# STM32WBA62xx register map
File version: 1.0
Registers are 32-bit, read-write, reset 0x0 unless marked. A register's access mark holds for its fields unless they carry their own. Offsets are from the block's base; [hi:lo] are bit positions; {n}, {i} and the like mark numbered series.

## FLASH — FLASH Registers
Base 0x40022000
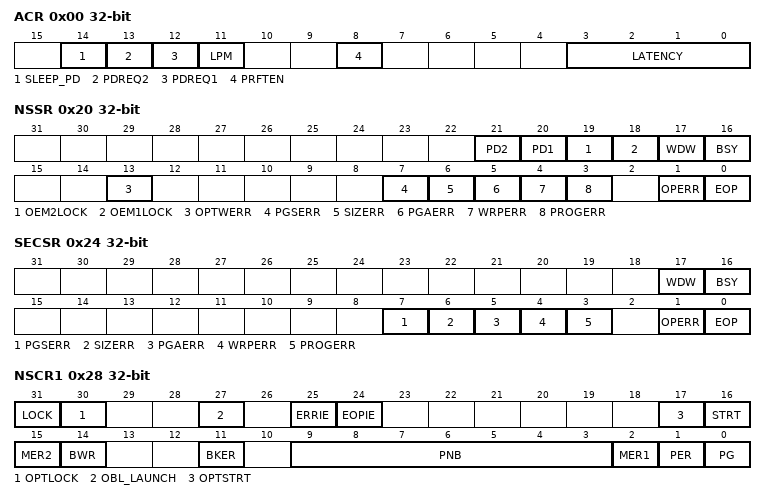
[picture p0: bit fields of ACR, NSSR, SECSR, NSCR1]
0x00 ACR — FLASH access control register
  [14] SLEEP_PD — Flash power-down mode during sleep
  [13] PDREQ2 — Flash bank 2 power-down mode request
  [12] PDREQ1 — Flash bank 1 power-down mode request
  [11] LPM — Low-Power read mode
  [8] PRFTEN — Prefetch enable
  [3:0] LATENCY
    0=FLASH Zero wait state; 1=FLASH One wait state; 2=FLASH Two wait states; 3=FLASH Three wait states; 4=FLASH Four wait states; 5=FLASH Five wait state; 6=FLASH Six wait state; 7=FLASH Seven wait states; 8=FLASH Eight wait states; 9=FLASH Nine wait states; 10=FLASH Ten wait state; 11=FLASH Eleven wait state; 12=FLASH Twelve wait states; 13=FLASH Thirteen wait states; 14=FLASH Fourteen wait states; 15=FLASH Fifteen wait states
0x08 NSKEYR — FLASH non-secure key register
  [31:0] NSKEY — Flash memory non-secure key
0x0C SECKEYR — FLASH secure key register
  [31:0] SECKEY — Flash memory secure key
0x10 OPTKEYR — FLASH option key register
  [31:0] OPTKEY — Option byte key
0x18 PDKEY1R — FLASH Bank 1 power-down key register
  [31:0] PDKEY — Flash bank 1 power-down key
0x1C PDKEY2R — FLASH Bank 2 power-down key register
  [31:0] PDKEY — Flash bank 2 power-down key
0x20 NSSR — FLASH non-secure status register
  [21] PD2 — Flash bank 2 in power-down mode
  [20] PD1 — Flash bank 1 in power-down mode
  [19] OEM2LOCK
  [18] OEM1LOCK
  [17] WDW — Non-secure wait data to write
  [16] BSY — Non-secure busy
  [13] OPTWERR — Option write error
  [7] PGSERR — Non-secure programming sequence error
  [6] SIZERR — Non-secure size error
  [5] PGAERR — Non-secure programming alignment error
  [4] WRPERR — Non-secure write protection error
  [3] PROGERR — Non-secure programming error
  [1] OPERR — Non-secure operation error
  [0] EOP — Non-secure end of operation
0x24 SECSR — FLASH secure status register
  [17] WDW — Secure wait data to write
  [16] BSY — Secure busy
  [7] PGSERR — Secure programming sequence error
  [6] SIZERR — Secure size error
  [5] PGAERR — Secure programming alignment error
  [4] WRPERR — Secure write protection error
  [3] PROGERR — Secure programming error
  [1] OPERR — Secure operation error
  [0] EOP — Secure end of operation
0x28 NSCR1 — FLASH non-secure control register
  [31] LOCK — Non-secure Lock
  [30] OPTLOCK — Option Lock
  [27] OBL_LAUNCH — Force the option byte loading
  [25] ERRIE — Non-secure error interrupt enable
  [24] EOPIE — Non-secure End of operation interrupt enable
  [17] OPTSTRT — Option Modification Start
  [16] STRT — Non-secure Start
  [15] MER2 — Non-secure Flash Bank 2 Erase
  [14] BWR — Non-secure Burst Write Programming mode
  [11] BKER — Non-secure Bank Selection for Page Erase
  [9:3] PNB — Non-secure Page Number selection
  [2] MER1 — Non-secure Flash Bank 1 Erase
  [1] PER — Non-secure Page Erase
  [0] PG — Non-secure Programming
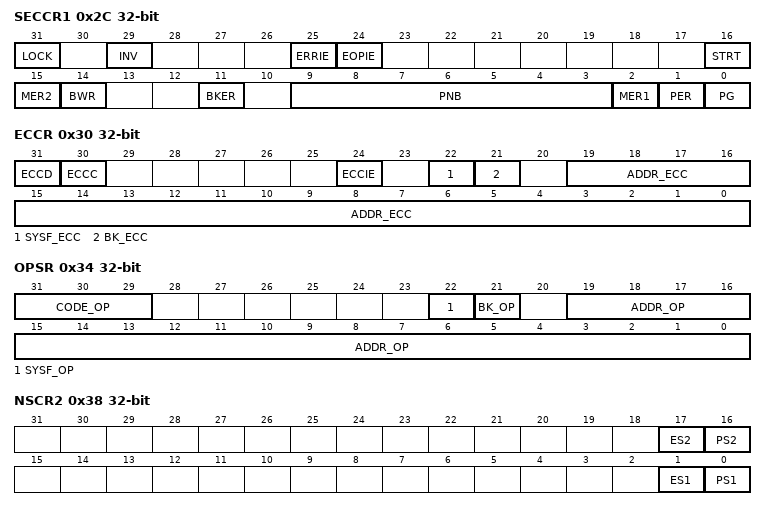
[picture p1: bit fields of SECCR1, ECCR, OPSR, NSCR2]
0x2C SECCR1 — FLASH secure control register
  [31] LOCK — Secure Lock
  [29] INV — Flash Security State Invert
  [25] ERRIE — Secure error interrupt enable
  [24] EOPIE — Secure end of operation interrupt enable
  [16] STRT — Secure Start
  [15] MER2 — Secure Flash Bank 2 Erase
  [14] BWR — Secure Burst Write programming mode
  [11] BKER — Secure Bank Selection for Page Erase
  [9:3] PNB — Secure Page Number selection
  [2] MER1 — Secure Flash Bank 1 Erase
  [1] PER — Secure Page Erase
  [0] PG — Secure Programming
0x30 ECCR — FLASH ECC register
  [31] ECCD — ECC detection
  [30] ECCC — ECC correction
  [24] ECCIE — ECC correction interrupt enable
  [22] SYSF_ECC — System Flash ECC fail
  [21] BK_ECC — Bank ECC fail
  [19:0] ADDR_ECC — ECC fail address
0x34 OPSR — FLASH OPSR register
  [31:29] CODE_OP — Flash memory operation code
  [22] SYSF_OP — Operation in system Flash memory interrupted
  [21] BK_OP — Operation in bank interrupted
  [19:0] ADDR_OP — Interrupted operation address
0x38 NSCR2 — FLASH non-secure control register
  [17] ES2 — Bank 2 non-secure erase suspend request
  [16] PS2 — Bank 2 non-secure program suspend request
  [1] ES1 — Bank 1 non-secure erase suspend request
  [0] PS1 — Bank 1 non-secure program suspend request
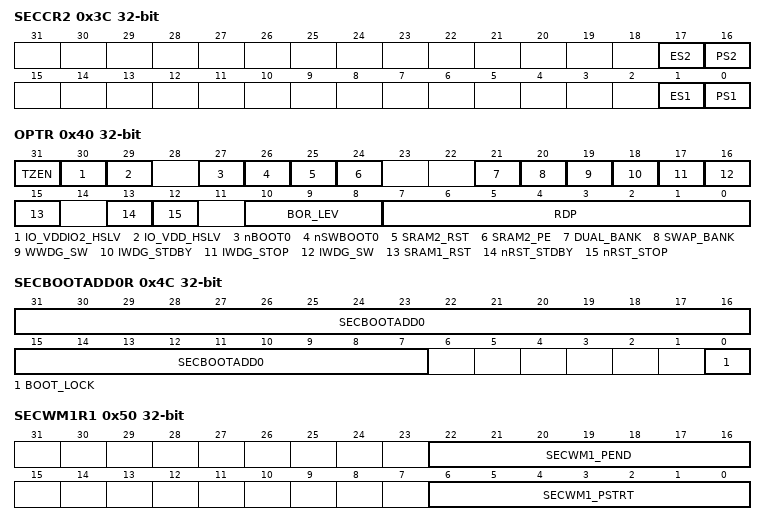
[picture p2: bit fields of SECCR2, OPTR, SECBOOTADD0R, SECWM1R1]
0x3C SECCR2 — FLASH secure control register
  [17] ES2 — Bank 2 secure erase suspend request
  [16] PS2 — Bank 2 secure program suspend request
  [1] ES1 — Bank 1 secure erase suspend request
  [0] PS1 — Bank 1 secure program suspend request
0x40 OPTR — FLASH option control register
  [31] TZEN — Global TrustZone security enable
  [30] IO_VDDIO2_HSLV — High-speed IO at low Vddio2 voltage configuration
  [29] IO_VDD_HSLV — High-speed IO at low Vdd voltage configuration
  [27] nBOOT0 — nBOOT0 option bit
  [26] nSWBOOT0 — Software BOOT0
  [25] SRAM2_RST — SRAM2 erase when system reset
  [24] SRAM2_PE — SRAM2 ECC detection and correction enable
  [21] DUAL_BANK
  [20] SWAP_BANK
  [19] WWDG_SW — Window watchdog selection
  [18] IWDG_STDBY — Independent watchdog counter freeze in Standby mode
  [17] IWDG_STOP — Independent watchdog counter freeze in Stop mode
  [16] IWDG_SW — Independent watchdog selection
  [15] SRAM1_RST — SRAM1 erase upon system reset
  [13] nRST_STDBY
  [12] nRST_STOP
  [10:8] BOR_LEV — BOR reset Level
  [7:0] RDP — Readout protection level
0x44 NSBOOTADD0R — FLASH non-secure boot address 0 register
  [31:7] NSBOOTADD0 — Non-secure boot address 0
0x48 NSBOOTADD1R — FLASH non-secure boot address 1 register
  [31:7] NSBOOTADD1 — Non-secure boot address 1
0x4C SECBOOTADD0R — FLASH secure boot address 0 register
  [31:7] SECBOOTADD0 — Secure boot address 0
  [0] BOOT_LOCK
0x50 SECWM1R1 — FLASH bank 1 secure watermark1 register 1
  [22:16] SECWM1_PEND — Bank 1 end page of secure area
  [6:0] SECWM1_PSTRT — Bank 1 start page of secure area
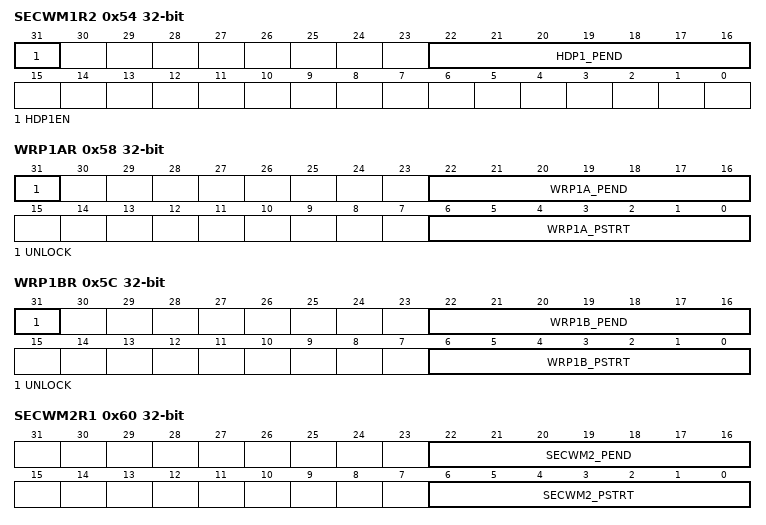
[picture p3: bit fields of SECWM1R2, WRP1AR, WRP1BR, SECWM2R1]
0x54 SECWM1R2 — FLASH bank 1 secure watermark1 register 2
  [31] HDP1EN — Bank 1 secure hide protection area enable
  [22:16] HDP1_PEND — Bank 1 end page of secure hide protection area
0x58 WRP1AR — FLASH WRP bank 1 area A address register
  [31] UNLOCK — WPR bank 1 area A unlock
  [22:16] WRP1A_PEND — WPR bank 1 area A end page
  [6:0] WRP1A_PSTRT — WPR bank 1 area A start page
0x5C WRP1BR — FLASH WRP bank 1 area B address register
  [31] UNLOCK — WPR bank 1 area B unlock
  [22:16] WRP1B_PEND — WPR bank 1 area B end page
  [6:0] WRP1B_PSTRT — WPR bank 1 area B start page
0x60 SECWM2R1 — FLASH bank 2 secure watermark2 register 1
  [22:16] SECWM2_PEND — Bank 2 end page of secure area
  [6:0] SECWM2_PSTRT — Bank 2 start page of secure area
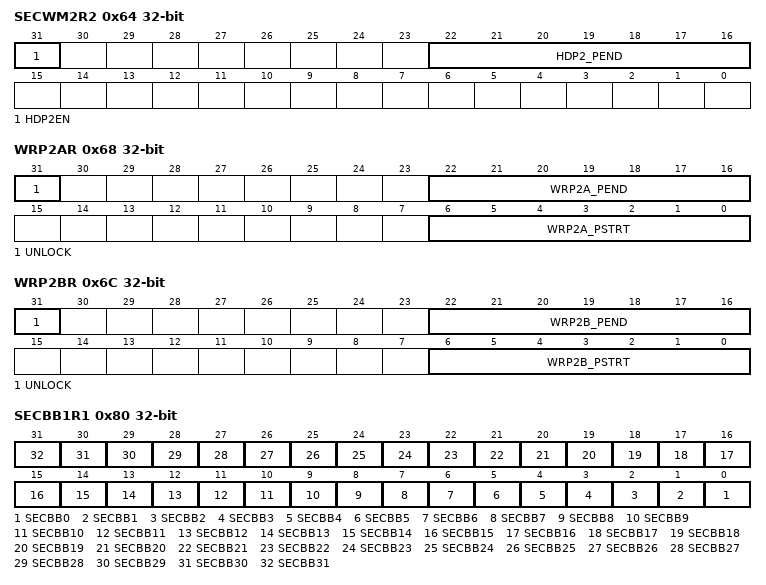
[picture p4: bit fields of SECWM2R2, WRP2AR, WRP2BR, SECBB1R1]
0x64 SECWM2R2 — FLASH bank 2 secure watermark2 register 2
  [31] HDP2EN — Bank 2 secure hide protection area enable
  [22:16] HDP2_PEND — Bank 2 end page of secure hide protection area
0x68 WRP2AR — FLASH WRP bank 2 area A address register
  [31] UNLOCK — WPR bank 2 area A unlock
  [22:16] WRP2A_PEND — WPR bank 2 area A end page
  [6:0] WRP2A_PSTRT — WPR bank 2 area A start page
0x6C WRP2BR — FLASH WRP bank 2 area B address register
  [31] UNLOCK — WPR bank 2 area B unlock
  [22:16] WRP2B_PEND — WPR bank 2 area B end page
  [6:0] WRP2B_PSTRT — WPR bank 2 area B start page
0x70 OEM1KEYR1 — FLASH OEM1 key register 1
  [31:0] OEM1KEY — OEM1 least significant bytes key
0x74 OEM1KEYR2 — FLASH OEM1 key register 2
  [31:0] OEM1KEY — OEM1 most significant bytes key
0x78 OEM2KEYR1 — FLASH OEM2 key register 1
  [31:0] OEM2KEY — OEM2 least significant bytes key
0x7C OEM2KEYR2 — FLASH OEM2 key register 2
  [31:0] OEM2KEY — OEM2 most significant bytes key
0x80 SECBB1R1 — FLASH bank 1 secure block-based bank register 1
  [n] SECBB{n} (n=0..31) — Page {n} in Flash bank 1 block-based secure
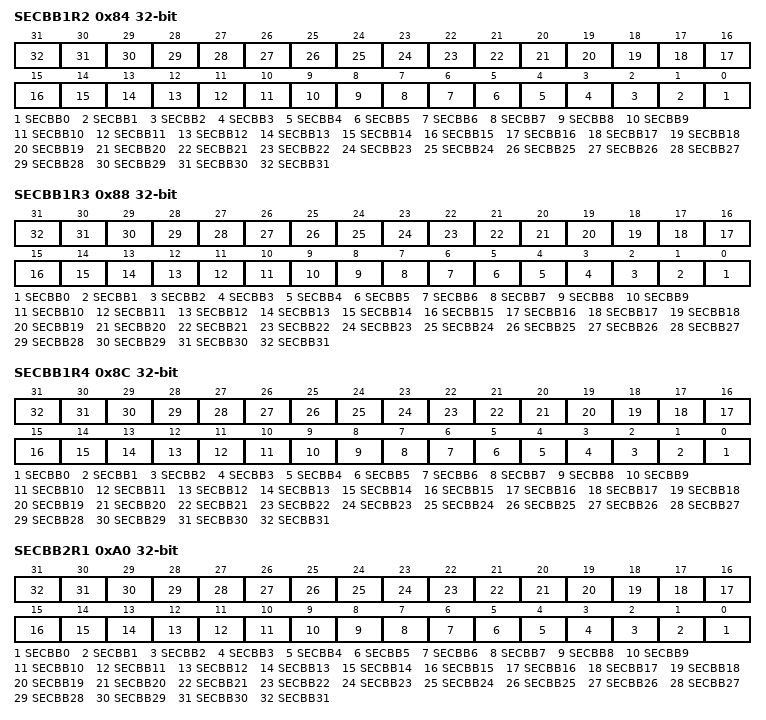
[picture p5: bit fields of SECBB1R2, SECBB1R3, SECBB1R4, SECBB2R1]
0x84 SECBB1R2 — FLASH bank 1 secure block-based bank register 2
  [n] SECBB{n} (n=0..31) — Page {n+32} in Flash bank 1 block-based secure
0x88 SECBB1R3 — FLASH bank 1 secure block-based bank register 3
  [n] SECBB{n} (n=0..31) — Page {n+64} in Flash bank 1 block-based secure
0x8C SECBB1R4 — FLASH bank 1 secure block-based bank register 4
  [n] SECBB{n} (n=0..31) — Page {n+96} in Flash bank 1 block-based secure
0xA0 SECBB2R1 — FLASH bank 2 secure block-based bank register 1
  [n] SECBB{n} (n=0..31) — Page {n} in Flash bank 2 block-based secure
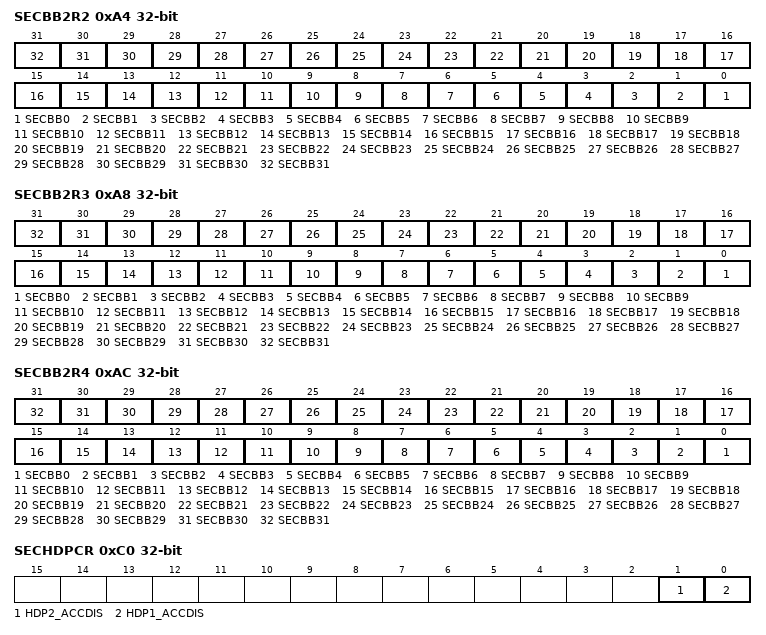
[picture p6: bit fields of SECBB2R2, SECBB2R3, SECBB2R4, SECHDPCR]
0xA4 SECBB2R2 — FLASH bank 2 secure block-based bank register 2
  [n] SECBB{n} (n=0..31) — Page {n+32} in Flash bank 2 block-based secure
0xA8 SECBB2R3 — FLASH bank 2 secure block-based bank register 3
  [n] SECBB{n} (n=0..31) — Page {n+64} in Flash bank 2 block-based secure
0xAC SECBB2R4 — FLASH bank 2 secure block-based bank register 4
  [n] SECBB{n} (n=0..31) — Page {n+96} in Flash bank 2 block-based secure
0xC0 SECHDPCR — FLASH secure HDP control register
  [1] HDP2_ACCDIS — Bank 2 secure HDP area access disable
  [0] HDP1_ACCDIS — Bank 1 secure HDP area access disable
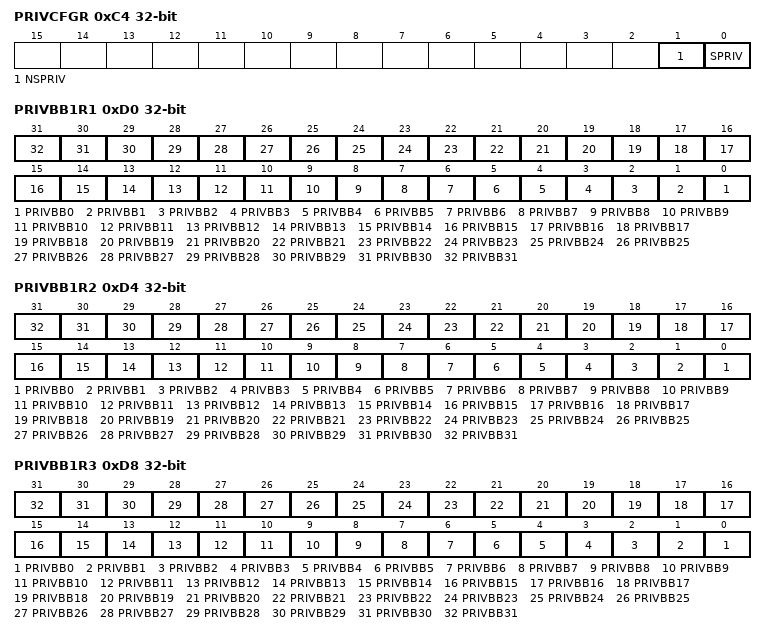
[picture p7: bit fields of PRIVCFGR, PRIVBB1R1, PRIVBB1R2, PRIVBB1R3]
0xC4 PRIVCFGR — FLASH privilege configuration register
  [1] NSPRIV — Privilege protection for non-secure registers
  [0] SPRIV — Privilege protection for secure registers
0xD0 PRIVBB1R1 — FLASH bank 1 privilege block-based bank register 1
  [n] PRIVBB{n} (n=0..31) — Page {n} in Flash bank 1 only accessible by privileged access
0xD4 PRIVBB1R2 — FLASH bank 1 privilege block-based bank register 2
  [n] PRIVBB{n} (n=0..31) — Page {n+32} in Flash bank 1 only accessible by privileged access
0xD8 PRIVBB1R3 — FLASH bank 1 privilege block-based bank register 3
  [n] PRIVBB{n} (n=0..31) — Page {n+64} in Flash bank 1 only accessible by privileged access
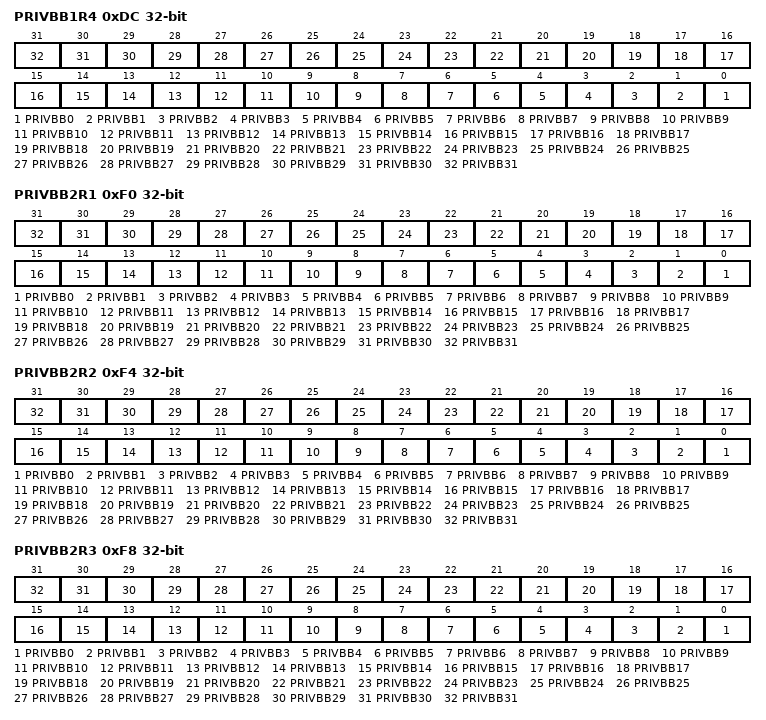
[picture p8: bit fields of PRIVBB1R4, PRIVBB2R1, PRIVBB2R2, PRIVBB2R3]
0xDC PRIVBB1R4 — FLASH bank 1 privilege block-based bank register 4
  [n] PRIVBB{n} (n=0..31) — Page {n+96} in Flash bank 1 only accessible by privileged access
0xF0 PRIVBB2R1 — FLASH bank 2 privilege block-based bank register 1
  [n] PRIVBB{n} (n=0..31) — Page {n} in Flash bank 2 only accessible by privileged access
0xF4 PRIVBB2R2 — FLASH bank 2 privilege block-based bank register 2
  [n] PRIVBB{n} (n=0..31) — Page {n+32} in Flash bank 2 only accessible by privileged access
0xF8 PRIVBB2R3 — FLASH bank 2 privilege block-based bank register 3
  [n] PRIVBB{n} (n=0..31) — Page {n+64} in Flash bank 2 only accessible by privileged access
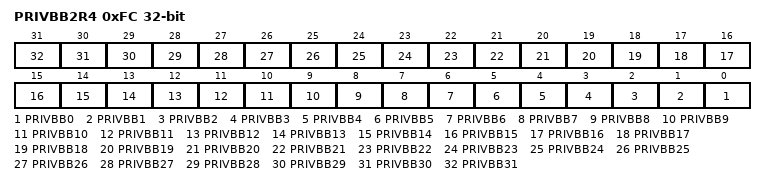
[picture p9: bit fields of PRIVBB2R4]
0xFC PRIVBB2R4 — FLASH bank 2 privilege block-based bank register 4
  [n] PRIVBB{n} (n=0..31) — Page {n+96} in Flash bank 2 only accessible by privileged access
